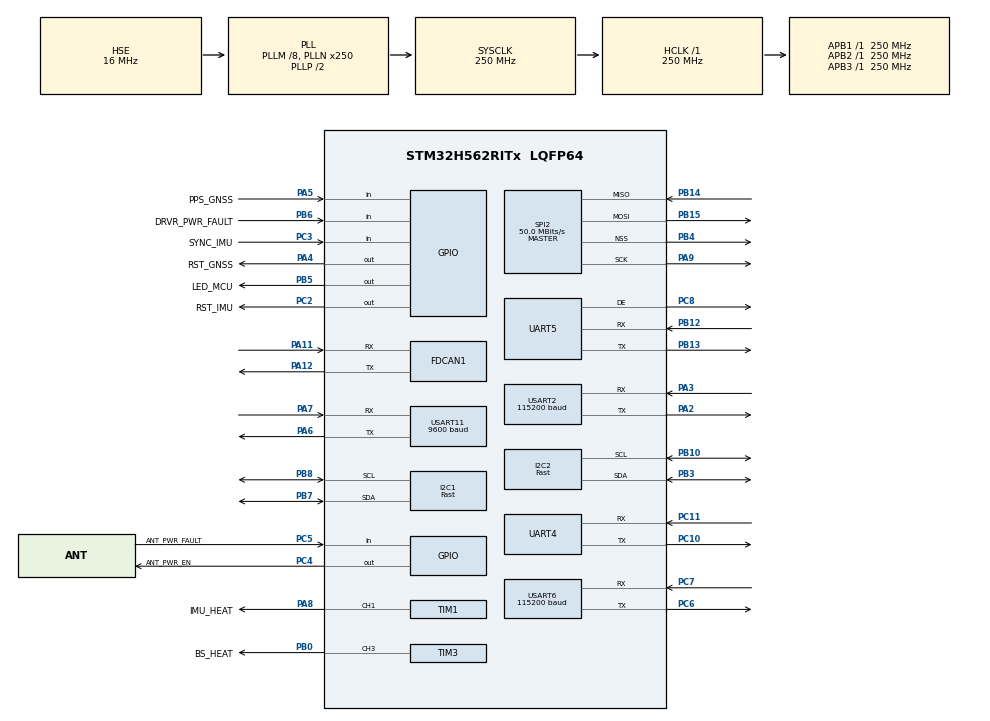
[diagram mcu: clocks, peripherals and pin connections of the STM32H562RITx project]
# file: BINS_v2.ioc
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BOOTPATH.BootPathName=LEGACY
BOOTPATH.UserSelectedBootPath=LEGACY
CORTEX_M33_NS.userName=CORTEX_M33
FDCAN1.AutoRetransmission=ENABLE
FDCAN1.CalculateBaudRateNominal=400000
FDCAN1.CalculateTimeBitNominal=2500
FDCAN1.CalculateTimeQuantumNominal=100.0
FDCAN1.ClockDivider=FDCAN_CLOCK_DIV1
FDCAN1.DataPrescaler=10
FDCAN1.DataTimeSeg1=18
FDCAN1.DataTimeSeg2=6
FDCAN1.FrameFormat=FDCAN_FRAME_CLASSIC
FDCAN1.NominalPrescaler=10
FDCAN1.NominalTimeSeg1=18
FDCAN1.NominalTimeSeg2=6
FDCAN1.ProtocolException=DISABLE
FDCAN1.RxBuffersNbr=1
FDCAN1.RxFifo0ElmtsNbr=64
FDCAN1.StdFiltersNbr=0
FDCAN1.TransmitPause=DISABLE
FDCAN1.TxBuffersNbr=0
FDCAN1.TxFifoQueueElmtsNbr=32
FLASH.advanced_settings=false
I2C1.I2C_Speed_Mode=I2C_Fast
I2C1.Timing=0x10C043E5
I2C2.I2C_Speed_Mode=I2C_Fast
I2C2.Timing=0x10C043E5
Mcu.Family=STM32H5
Mcu.Name=STM32H562RITx
Mcu.Package=LQFP64
Mcu.UserConstants=i2c_bmp,$$_I2C1_IP_HANDLE_$$;uart_gnss,$$_USART11_IP_HANDLE_$$;i2c_temp,$$_I2C2_IP_HANDLE_$$;uart_mti,$$_USART2_IP_HANDLE_$$;uart_232,$$_UART4_IP_HANDLE_$$;uart_485,$$_UART5_IP_HANDLE_$$;uart_422,$$_USART6_IP_HANDLE_$$;can,$$_FDCAN1_IP_HANDLE_$$
NVIC.PriorityGroup=NVIC_PRIORITYGROUP_4
NVIC.TIM17_IRQn=true\:15\:0\:false\:false\:true\:false\:true\:true
NVIC.TimeBase=TIM17_IRQn
NVIC.TimeBaseIP=TIM17
PA11.GPIO_Speed=GPIO_SPEED_FREQ_HIGH
PA11.Mode=FDCAN_Activate
PA11.Signal=FDCAN1_RX
PA12.GPIO_Speed=GPIO_SPEED_FREQ_HIGH
PA12.Mode=FDCAN_Activate
PA12.Signal=FDCAN1_TX
PA13(JTMS/SWDIO).Mode=Serial_Wire
PA13(JTMS/SWDIO).Signal=DEBUG_JTMS-SWDIO
PA14(JTCK/SWCLK).Mode=Serial_Wire
PA14(JTCK/SWCLK).Signal=DEBUG_JTCK-SWCLK
PA2.GPIO_Speed=GPIO_SPEED_FREQ_HIGH
PA2.Mode=Asynchronous
PA2.Signal=USART2_TX
PA3.GPIO_Speed=GPIO_SPEED_FREQ_HIGH
PA3.Mode=Asynchronous
PA3.Signal=USART2_RX
PA4.GPIO_Label=RST_GNSS
PA4.Signal=GPIO_Output
PA5.GPIO_Label=PPS_GNSS
PA5.Signal=GPIO_Input
PA6.GPIO_Speed=GPIO_SPEED_FREQ_HIGH
PA6.Mode=Asynchronous
PA6.Signal=USART11_TX
PA7.GPIO_Speed=GPIO_SPEED_FREQ_HIGH
PA7.Mode=Asynchronous
PA7.Signal=USART11_RX
PA8.GPIO_Label=IMU_HEAT
PA8.Signal=S_TIM1_CH1
PA9.Mode=Full_Duplex_Master
PA9.Signal=SPI2_SCK
PB0.GPIO_Label=BS_HEAT
PB0.Signal=S_TIM3_CH3
PB10.GPIO_Speed=GPIO_SPEED_FREQ_HIGH
PB10.Mode=I2C
PB10.Signal=I2C2_SCL
PB12.GPIO_Speed=GPIO_SPEED_FREQ_HIGH
PB12.Mode=Asynchronous
PB12.Signal=UART5_RX
PB13.GPIO_Speed=GPIO_SPEED_FREQ_HIGH
PB13.Mode=Asynchronous
PB13.Signal=UART5_TX
PB14.Mode=Full_Duplex_Master
PB14.Signal=SPI2_MISO
PB15.Mode=Full_Duplex_Master
PB15.Signal=SPI2_MOSI
PB3(JTDO/TRACESWO).GPIO_Speed=GPIO_SPEED_FREQ_HIGH
PB3(JTDO/TRACESWO).Mode=I2C
PB3(JTDO/TRACESWO).Signal=I2C2_SDA
PB4(NJTRST).Mode=NSS_Signal_Hard_Output
PB4(NJTRST).Signal=SPI2_NSS
PB5.GPIO_Label=LED_MCU
PB5.PinState=GPIO_PIN_SET
PB5.Signal=GPIO_Output
PB6.GPIO_Label=DRVR_PWR_FAULT
PB6.Signal=GPIO_Input
PB7.GPIO_Speed=GPIO_SPEED_FREQ_HIGH
PB7.Mode=I2C
PB7.Signal=I2C1_SDA
PB8.GPIO_Speed=GPIO_SPEED_FREQ_HIGH
PB8.Mode=I2C
PB8.Signal=I2C1_SCL
PC10.GPIO_Speed=GPIO_SPEED_FREQ_HIGH
PC10.Mode=Asynchronous
PC10.Signal=UART4_TX
PC11.GPIO_Speed=GPIO_SPEED_FREQ_HIGH
PC11.Mode=Asynchronous
PC11.Signal=UART4_RX
PC2.GPIO_Label=RST_IMU
PC2.Signal=GPIO_Output
PC3.GPIO_Label=SYNC_IMU
PC3.Signal=GPIO_Input
PC4.GPIO_Label=ANT_PWR_EN
PC4.Signal=GPIO_Output
PC5.GPIO_Label=ANT_PWR_FAULT
PC5.Signal=GPIO_Input
PC6.GPIO_Speed=GPIO_SPEED_FREQ_HIGH
PC6.Mode=Asynchronous
PC6.Signal=USART6_TX
PC7.GPIO_Speed=GPIO_SPEED_FREQ_HIGH
PC7.Mode=Asynchronous
PC7.Signal=USART6_RX
PC8.GPIO_Speed=GPIO_SPEED_FREQ_HIGH
PC8.Mode=Hardware Flow Control (RS485)
PC8.Signal=UART5_DE
PH0-OSC_IN(PH0).Mode=HSE-External-Oscillator
PH0-OSC_IN(PH0).Signal=RCC_OSC_IN
PH1-OSC_OUT(PH1).Mode=HSE-External-Oscillator
PH1-OSC_OUT(PH1).Signal=RCC_OSC_OUT
ProjectManager.HeapSize=0x200
ProjectManager.StackSize=0x400
ProjectManager.TargetToolchain=STM32CubeIDE
RCC.ADCFreq_Value=250000000
RCC.AHBFreq_Value=250000000
RCC.APB1Freq_Value=250000000
RCC.APB1TimFreq_Value=250000000
RCC.APB2Freq_Value=250000000
RCC.APB2TimFreq_Value=250000000
RCC.APB3Freq_Value=250000000
RCC.CSI_VALUE=4000000
RCC.CortexFreq_Value=250000000
RCC.EPOD_VALUE=16000000
RCC.FDCANClockSelection=RCC_FDCANCLKSOURCE_PLL1Q
RCC.HCLKFreq_Value=250000000
RCC.HSE_VALUE=16000000
RCC.HSI48_VALUE=48000000
RCC.HSI_VALUE=64000000
RCC.LSE_VALUE=32768
RCC.LSIRC_VALUE=32000
RCC.PLL1Q=5
RCC.PLL2M=8
RCC.PLL2N=250
RCC.PLL2P=5
RCC.PLL2Q=5
RCC.PLL2Source=RCC_PLL2_SOURCE_HSE
RCC.PLL3M=8
RCC.PLL3N=250
RCC.PLL3P=5
RCC.PLL3Q=5
RCC.PLL3R=5
RCC.PLL3Source=RCC_PLL3_SOURCE_HSE
RCC.PLLM=8
RCC.PLLN=250
RCC.PLLSourceVirtual=RCC_PLL1_SOURCE_HSE
RCC.SYSCLKFreq_VALUE=250000000
RCC.SYSCLKSource=RCC_SYSCLKSOURCE_PLLCLK
RCC.USBFreq_Value=48000000
RCC.VCOOutputFreq_Value=500000000
SH.S_TIM1_CH1.0=TIM1_CH1,PWM Generation1 CH1
SH.S_TIM3_CH3.0=TIM3_CH3,PWM Generation3 CH3
SPI2.BaudRatePrescaler=SPI_BAUDRATEPRESCALER_2
SPI2.CalculateBaudRate=50.0 MBits/s
SPI2.Direction=SPI_DIRECTION_2LINES
SPI2.Mode=SPI_MODE_MASTER
SPI2.VirtualNSS=VM_NSSHARD
SPI2.VirtualType=VM_MASTER
TIM1.Channel-PWM\ Generation1\ CH1=TIM_CHANNEL_1
TIM3.Channel-PWM\ Generation3\ CH3=TIM_CHANNEL_3
UART4.DMADisableonRxErrorParam=UART_ADVFEATURE_DMA_DISABLEONRXERROR
UART4.FIFOMode=FIFOMODE_ENABLE
UART4.OverrunDisableParam=UART_ADVFEATURE_OVERRUN_ENABLE
UART4.RXFIFOThreshold=RXFIFO_THRESHOLD_7EIGHTHFULL
UART5.DMADisableonRxErrorParam=UART_ADVFEATURE_DMA_DISABLEONRXERROR
UART5.FIFOMode=FIFOMODE_ENABLE
UART5.OverrunDisableParam=UART_ADVFEATURE_OVERRUN_ENABLE
UART5.RXFIFOThreshold=RXFIFO_THRESHOLD_7EIGHTHFULL
USART11.BaudRate=9600
USART11.DMADisableonRxErrorParam=ADVFEATURE_DMA_DISABLEONRXERROR
USART11.FIFOMode=FIFOMODE_ENABLE
USART11.OverrunDisableParam=ADVFEATURE_OVERRUN_ENABLE
USART11.RXFIFOThreshold=RXFIFO_THRESHOLD_7EIGHTHFULL
USART11.VirtualMode=VM_ASYNC
USART11.VirtualMode-Asynchronous=VM_ASYNC
USART2.BaudRate=115200
USART2.DMADisableonRxErrorParam=ADVFEATURE_DMA_DISABLEONRXERROR
USART2.FIFOMode=FIFOMODE_ENABLE
USART2.OverrunDisableParam=ADVFEATURE_OVERRUN_ENABLE
USART2.RXFIFOThreshold=RXFIFO_THRESHOLD_7EIGHTHFULL
USART2.SwapParam=ADVFEATURE_SWAP_DISABLE
USART2.VirtualMode-Asynchronous=VM_ASYNC
USART6.BaudRate=115200
USART6.DMADisableonRxErrorParam=ADVFEATURE_DMA_DISABLEONRXERROR
USART6.FIFOMode=FIFOMODE_ENABLE
USART6.OverrunDisableParam=ADVFEATURE_OVERRUN_ENABLE
USART6.RXFIFOThreshold=RXFIFO_THRESHOLD_7EIGHTHFULL
USART6.VirtualMode=VM_ASYNC
VP_BOOTPATH_VS_BOOTPATH.Mode=BP_Activate
VP_CORTEX_M33_NS_VS_Ext.Mode=External_Mode
VP_DCACHE1_VS_DCACHE.Mode=DCACHE_Activate
VP_FLASH_SIG_Activate_FlashIP.Mode=Activate_FlashIP
VP_ICACHE_VS_ICACHE.Mode=DefaultMode
VP_MEMORYMAP_VS_MEMORYMAP.Mode=CurAppReg
VP_PWR_VS_DBSignals.Mode=DisableDeadBatterySignals
VP_PWR_VS_LPOM.Mode=PowerOptimisation
VP_PWR_VS_SECSignals.Mode=Security/Privilege
VP_SYS_VS_tim17.Mode=TIM17
VP_TIM3_VS_ClockSourceINT.Mode=Internal
board=custom

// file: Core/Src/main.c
/* USER CODE BEGIN Header */
/**
  ******************************************************************************
  * @file           : main.c
  * @brief          : Main program body
  ******************************************************************************
  * @attention
  *
  * Copyright (c) 2025 STMicroelectronics.
  * All rights reserved.
  *
  * This software is licensed under terms that can be found in the LICENSE file
  * in the root directory of this software component.
  * If no LICENSE file comes with this software, it is provided AS-IS.
  *
  ******************************************************************************
  */
/* USER CODE END Header */
#include "main.h"
#include "dcache.h"
#include "fdcan.h"
#include "flash.h"
#include "i2c.h"
#include "icache.h"
#include "memorymap.h"
#include "spi.h"
#include "tim.h"
#include "usart.h"
#include "gpio.h"

/* USER CODE BEGIN Includes */
#include "app.h"
/* USER CODE END Includes */

void SystemClock_Config(void);
/* USER CODE BEGIN PFP */
void freertos_init(void);
/* USER CODE END PFP */

int main(void)
{

  /* MCU Configuration--------------------------------------------------------*/

  /* Reset of all peripherals, Initializes the Flash interface and the Systick. */
  HAL_Init();

  /* Configure the system clock */
  SystemClock_Config();

  /* Initialize all configured peripherals */
  MX_GPIO_Init();
  MX_FDCAN1_Init();
  MX_I2C1_Init();
  MX_I2C2_Init();
  MX_UART4_Init();
  MX_UART5_Init();
  MX_USART2_UART_Init();
  MX_USART6_UART_Init();
  MX_USART11_UART_Init();
  MX_TIM3_Init();
  MX_SPI2_Init();
  MX_TIM1_Init();
  MX_DCACHE1_Init();
  MX_FLASH_Init();
  MX_ICACHE_Init();
  /* USER CODE BEGIN 2 */
  app_run();

  /* USER CODE END 2 */

  /* Infinite loop */
  while (1)
  {

  }
}

void SystemClock_Config(void)
{
  RCC_OscInitTypeDef RCC_OscInitStruct = {0};
  RCC_ClkInitTypeDef RCC_ClkInitStruct = {0};

  /** Configure the main internal regulator output voltage
  */
  __HAL_PWR_VOLTAGESCALING_CONFIG(PWR_REGULATOR_VOLTAGE_SCALE0);

  while(!__HAL_PWR_GET_FLAG(PWR_FLAG_VOSRDY)) {}

  /** Initializes the RCC Oscillators according to the specified parameters
  * in the RCC_OscInitTypeDef structure.
  */
  RCC_OscInitStruct.OscillatorType = RCC_OSCILLATORTYPE_HSE;
  RCC_OscInitStruct.HSEState = RCC_HSE_ON;
  RCC_OscInitStruct.PLL.PLLState = RCC_PLL_ON;
  RCC_OscInitStruct.PLL.PLLSource = RCC_PLL1_SOURCE_HSE;
  RCC_OscInitStruct.PLL.PLLM = 8;
  RCC_OscInitStruct.PLL.PLLN = 250;
  RCC_OscInitStruct.PLL.PLLP = 2;
  RCC_OscInitStruct.PLL.PLLQ = 5;
  RCC_OscInitStruct.PLL.PLLR = 2;
  RCC_OscInitStruct.PLL.PLLRGE = RCC_PLL1_VCIRANGE_1;
  RCC_OscInitStruct.PLL.PLLVCOSEL = RCC_PLL1_VCORANGE_WIDE;
  RCC_OscInitStruct.PLL.PLLFRACN = 0;
  if (HAL_RCC_OscConfig(&RCC_OscInitStruct) != HAL_OK)
  {
    Error_Handler();
  }

  /** Initializes the CPU, AHB and APB buses clocks
  */
  RCC_ClkInitStruct.ClockType = RCC_CLOCKTYPE_HCLK|RCC_CLOCKTYPE_SYSCLK
                              |RCC_CLOCKTYPE_PCLK1|RCC_CLOCKTYPE_PCLK2
                              |RCC_CLOCKTYPE_PCLK3;
  RCC_ClkInitStruct.SYSCLKSource = RCC_SYSCLKSOURCE_PLLCLK;
  RCC_ClkInitStruct.AHBCLKDivider = RCC_SYSCLK_DIV1;
  RCC_ClkInitStruct.APB1CLKDivider = RCC_HCLK_DIV1;
  RCC_ClkInitStruct.APB2CLKDivider = RCC_HCLK_DIV1;
  RCC_ClkInitStruct.APB3CLKDivider = RCC_HCLK_DIV1;

  if (HAL_RCC_ClockConfig(&RCC_ClkInitStruct, FLASH_LATENCY_5) != HAL_OK)
  {
    Error_Handler();
  }

   /* Select SysTick source clock */
  HAL_SYSTICK_CLKSourceConfig(SYSTICK_CLKSOURCE_HCLK);

   /* Re-Initialize Tick with new clock source */
  if (HAL_InitTick(TICK_INT_PRIORITY) != HAL_OK)
  {
    Error_Handler();
  }

  /** Configure the programming delay
  */
  __HAL_FLASH_SET_PROGRAM_DELAY(FLASH_PROGRAMMING_DELAY_2);
}

void HAL_TIM_PeriodElapsedCallback(TIM_HandleTypeDef *htim)
{
  if (htim->Instance == TIM17) {
    HAL_IncTick();
  }
}

void Error_Handler(void)
{
  __disable_irq();
  while (1)
  {
  }
}
